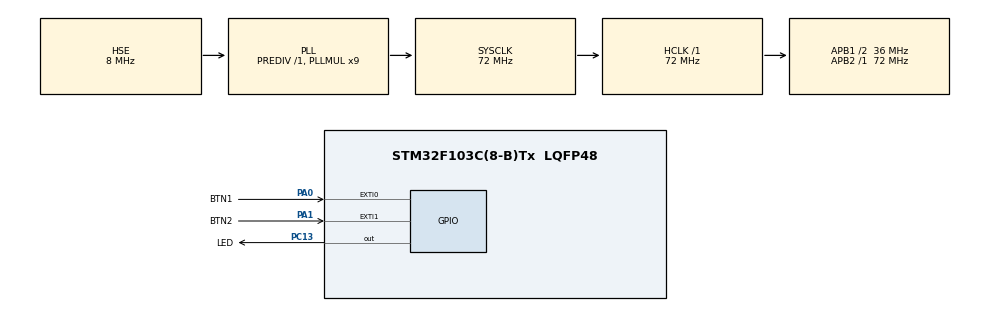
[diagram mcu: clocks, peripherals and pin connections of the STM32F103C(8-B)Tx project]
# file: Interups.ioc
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Mcu.Family=STM32F1
RCC.PLLSourceVirtual=RCC_PLLSOURCE_HSE
PD1-OSC_OUT.Mode=HSE-External-Oscillator
PC13-TAMPER-RTC.Signal=GPIO_Output
PD0-OSC_IN.Signal=RCC_OSC_IN
RCC.APB1CLKDivider=RCC_HCLK_DIV2
RCC.SYSCLKSource=RCC_SYSCLKSOURCE_PLLCLK
ProjectManager.StackSize=0x400
PA0-WKUP.GPIO_Label=BTN1
PA0-WKUP.Signal=GPXTI0
PD1-OSC_OUT.Signal=RCC_OSC_OUT
PA13.Signal=SYS_JTMS-SWDIO
NVIC.EXTI1_IRQn=true\:0\:0\:false\:false\:true\:true\:true
ProjectManager.TargetToolchain=STM32CubeIDE
RCC.HCLKFreq_Value=72000000
RCC.APB2TimFreq_Value=72000000
RCC.USBFreq_Value=72000000
PA1.GPIO_PuPd=GPIO_PULLDOWN
PA1.Signal=GPXTI1
RCC.AHBFreq_Value=72000000
PD0-OSC_IN.Mode=HSE-External-Oscillator
PB3.Mode=Trace_Asynchronous_SW
board=custom
PC13-TAMPER-RTC.GPIO_Label=LED
RCC.PLLMUL=RCC_PLL_MUL9
RCC.APB2Freq_Value=72000000
PA14.Mode=Trace_Asynchronous_SW
PA1.GPIO_Label=BTN2
PA13.Mode=Trace_Asynchronous_SW
Mcu.Name=STM32F103C(8-B)Tx
PB3.Signal=SYS_JTDO-TRACESWO
NVIC.EXTI0_IRQn=true\:0\:0\:false\:false\:true\:true\:true
RCC.SYSCLKFreq_VALUE=72000000
Mcu.Package=LQFP48
NVIC.TimeBase=TIM4_IRQn
NVIC.TimeBaseIP=TIM4
PA14.Signal=SYS_JTCK-SWCLK
ProjectManager.HeapSize=0x200
VP_SYS_VS_tim4.Mode=TIM4
NVIC.PriorityGroup=NVIC_PRIORITYGROUP_4
RCC.APB1TimFreq_Value=72000000
PA0-WKUP.GPIO_PuPd=GPIO_PULLDOWN
NVIC.TIM4_IRQn=true\:0\:0\:false\:false\:true\:false\:true
RCC.APB1Freq_Value=36000000

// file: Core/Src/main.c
/* USER CODE BEGIN Header */
/**
  ******************************************************************************
  * @file           : main.c
  * @brief          : Main program body
  ******************************************************************************
  * @attention
  *
  * <h2><center>&copy; Copyright (c) 2021 STMicroelectronics.
  * All rights reserved.</center></h2>
  *
  * This software component is licensed by ST under BSD 3-Clause license,
  * the "License"; You may not use this file except in compliance with the
  * License. You may obtain a copy of the License at:
  *                        opensource.org/licenses/BSD-3-Clause
  *
  ******************************************************************************
  */
/* USER CODE END Header */
#include "main.h"

/* USER CODE BEGIN Includes */
#include "stdio.h"
/* USER CODE END Includes */

void SystemClock_Config(void);
static void MX_GPIO_Init(void);

int main(void)
{

  /* MCU Configuration--------------------------------------------------------*/

  /* Reset of all peripherals, Initializes the Flash interface and the Systick. */
  HAL_Init();

  /* Configure the system clock */
  SystemClock_Config();

  /* Initialize all configured peripherals */
  MX_GPIO_Init();

  /* Infinite loop */
  /* USER CODE BEGIN WHILE */

  //while (i < 1000)
  for (int i = 0; i<=10; i++)
  {
    /* USER CODE END WHILE */

    /* USER CODE BEGIN 3 */
		printf("Hello World! %d \n", i);
		if (i == 10) {
			i = 0;
		}
		HAL_Delay(500);

  }
  /* USER CODE END 3 */
}

void SystemClock_Config(void)
{
  RCC_OscInitTypeDef RCC_OscInitStruct = {0};
  RCC_ClkInitTypeDef RCC_ClkInitStruct = {0};

  /** Initializes the RCC Oscillators according to the specified parameters
  * in the RCC_OscInitTypeDef structure.
  */
  RCC_OscInitStruct.OscillatorType = RCC_OSCILLATORTYPE_HSE;
  RCC_OscInitStruct.HSEState = RCC_HSE_ON;
  RCC_OscInitStruct.HSEPredivValue = RCC_HSE_PREDIV_DIV1;
  RCC_OscInitStruct.HSIState = RCC_HSI_ON;
  RCC_OscInitStruct.PLL.PLLState = RCC_PLL_ON;
  RCC_OscInitStruct.PLL.PLLSource = RCC_PLLSOURCE_HSE;
  RCC_OscInitStruct.PLL.PLLMUL = RCC_PLL_MUL9;
  if (HAL_RCC_OscConfig(&RCC_OscInitStruct) != HAL_OK)
  {
    Error_Handler();
  }
  /** Initializes the CPU, AHB and APB buses clocks
  */
  RCC_ClkInitStruct.ClockType = RCC_CLOCKTYPE_HCLK|RCC_CLOCKTYPE_SYSCLK
                              |RCC_CLOCKTYPE_PCLK1|RCC_CLOCKTYPE_PCLK2;
  RCC_ClkInitStruct.SYSCLKSource = RCC_SYSCLKSOURCE_PLLCLK;
  RCC_ClkInitStruct.AHBCLKDivider = RCC_SYSCLK_DIV1;
  RCC_ClkInitStruct.APB1CLKDivider = RCC_HCLK_DIV2;
  RCC_ClkInitStruct.APB2CLKDivider = RCC_HCLK_DIV1;

  if (HAL_RCC_ClockConfig(&RCC_ClkInitStruct, FLASH_LATENCY_2) != HAL_OK)
  {
    Error_Handler();
  }
}

static void MX_GPIO_Init(void)
{
  GPIO_InitTypeDef GPIO_InitStruct = {0};

  /* GPIO Ports Clock Enable */
  __HAL_RCC_GPIOC_CLK_ENABLE();
  __HAL_RCC_GPIOD_CLK_ENABLE();
  __HAL_RCC_GPIOA_CLK_ENABLE();
  __HAL_RCC_GPIOB_CLK_ENABLE();

  /*Configure GPIO pin Output Level */
  HAL_GPIO_WritePin(LED_GPIO_Port, LED_Pin, GPIO_PIN_RESET);

  /*Configure GPIO pin : LED_Pin */
  GPIO_InitStruct.Pin = LED_Pin;
  GPIO_InitStruct.Mode = GPIO_MODE_OUTPUT_PP;
  GPIO_InitStruct.Pull = GPIO_NOPULL;
  GPIO_InitStruct.Speed = GPIO_SPEED_FREQ_LOW;
  HAL_GPIO_Init(LED_GPIO_Port, &GPIO_InitStruct);

  /*Configure GPIO pins : BTN1_Pin BTN2_Pin */
  GPIO_InitStruct.Pin = BTN1_Pin|BTN2_Pin;
  GPIO_InitStruct.Mode = GPIO_MODE_IT_RISING;
  GPIO_InitStruct.Pull = GPIO_PULLDOWN;
  HAL_GPIO_Init(GPIOA, &GPIO_InitStruct);

  /* EXTI interrupt init*/
  HAL_NVIC_SetPriority(EXTI0_IRQn, 0, 0);
  HAL_NVIC_EnableIRQ(EXTI0_IRQn);

  HAL_NVIC_SetPriority(EXTI1_IRQn, 0, 0);
  HAL_NVIC_EnableIRQ(EXTI1_IRQn);

}

/* USER CODE BEGIN 4 */

/* Этот Callback закоментировал т.к. прописал в файле stm32f1xx_it.c в функции void EXTI0_IRQHandler(void) и void EXTI1_IRQHandler(void)

void HAL_GPIO_EXTI_Callback(uint16_t GPIO_Pin){
  if(GPIO_Pin==BTN1_Pin) {
    HAL_GPIO_WritePin(LED_GPIO_Port, LED_Pin, GPIO_PIN_SET);
    printf("LED is OFF \r\n"); // Отключен т.к. LED подключен по обратной схеме!
  } else if(GPIO_Pin==BTN2_Pin) {
    HAL_GPIO_WritePin(LED_GPIO_Port, LED_Pin, GPIO_PIN_RESET);
    printf("LED is ON \r\n"); // Катод подключен к PC13, а анод к питанию +3.3В.
  } else{
    __NOP(); //ничего не делаем
  }
}
*/
/* USER CODE END 4 */

 /**
  * @brief  Period elapsed callback in non blocking mode
  * @note   This function is called  when TIM4 interrupt took place, inside
  * HAL_TIM_IRQHandler(). It makes a direct call to HAL_IncTick() to increment
  * a global variable "uwTick" used as application time base.
  * @param  htim : TIM handle
  * @retval None
  */
void HAL_TIM_PeriodElapsedCallback(TIM_HandleTypeDef *htim)
{
  if (htim->Instance == TIM4) {
    HAL_IncTick();
  }
}

void Error_Handler(void)
{
  __disable_irq();
  while (1)
  {
  }
}

/************************ (C) COPYRIGHT STMicroelectronics *****END OF FILE****/
